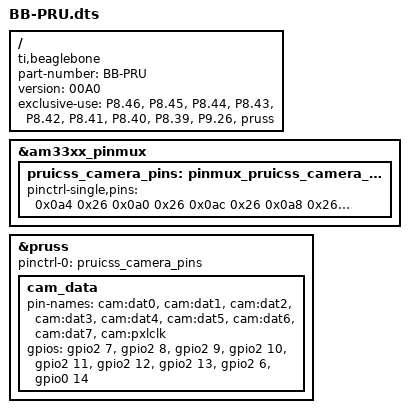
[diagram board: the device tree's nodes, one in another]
/dts-v1/;
/plugin/;

/ {
    compatible = "ti,beaglebone", "ti,beaglebone-black";

    /* identification */
    part-number = "BB-PRU";

    /* version */
    version = "00A0";

    /* state the resources this cape uses or prepare to get winged! */
    exclusive-use =
        /* the pin header P8 uses */
        "P8.46",
        "P8.45",
        "P8.44",
        "P8.43",
        "P8.42",
        "P8.41",
        "P8.40",
        "P8.39",
        "P9.26",
        /* Hardware IP cores in use */
        "pruss"; 

    fragment@0 {
        target = <&am33xx_pinmux>;
        __overlay__ {
            pruicss_camera_pins: pinmux_pruicss_camera_pins{
                pinctrl-single,pins = <
                    0x0a4 0x26
                    0x0a0 0x26
                    0x0ac 0x26
                    0x0a8 0x26
                    0x0b4 0x26
                    0x0b0 0x26
                    0x0bc 0x26
                    0x0b8 0x26
                    0x180 0x26
                >;
            };        

        };
    };

    fragment@1{
        target = <&pruss>;
        __overlay__{
            status = "okay";
            pinctrl-names = "default";
            pinctrl-0       = <&pruicss_camera_pins>;

            cam_data{
                pin-names     = "cam:dat0", "cam:dat1", "cam:dat2","cam:dat3","cam:dat4","cam:dat5","cam:dat6","cam:dat7","cam:pxlclk";
                gpios         = <&gpio2 7 0
                                &gpio2 8 0
                                &gpio2 9 0
                                &gpio2 10 0
                                &gpio2 11 0
                                &gpio2 12 0
                                &gpio2 13 0
				&gpio2 6 0
				&gpio0 14 0>;
            };            
/*            cam_control{
                pin-names     = "cam:pix_clk";        
                gpios         =<&gpio0 14 0>;
            };
*/
        };
    };
};
